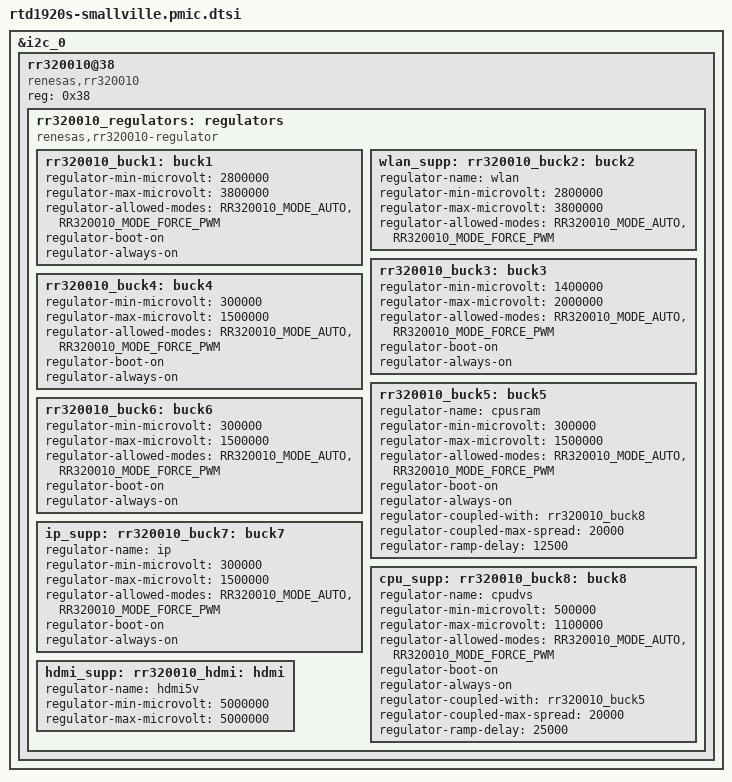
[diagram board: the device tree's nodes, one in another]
#include <dt-bindings/regulator/rr320010-regulator.h>

&i2c_0 {
	status = "okay";

	rr320010@38 {
		compatible = "renesas,rr320010";
		reg = <0x38>;

		rr320010_regulators: regulators {
			compatible = "renesas,rr320010-regulator";

			rr320010_buck1: buck1 {
				regulator-min-microvolt = <2800000>;
				regulator-max-microvolt = <3800000>;
				regulator-allowed-modes = <RR320010_MODE_AUTO>,
							  <RR320010_MODE_FORCE_PWM>;
				regulator-boot-on;
				regulator-always-on;
			};

			wlan_supp:
			rr320010_buck2: buck2 {
				regulator-name = "wlan";
				regulator-min-microvolt = <2800000>;
				regulator-max-microvolt = <3800000>;
				regulator-allowed-modes = <RR320010_MODE_AUTO>,
							  <RR320010_MODE_FORCE_PWM>;
			};

			rr320010_buck3: buck3 {
				regulator-min-microvolt = <1400000>;
				regulator-max-microvolt = <2000000>;
				regulator-allowed-modes = <RR320010_MODE_AUTO>,
							  <RR320010_MODE_FORCE_PWM>;
				regulator-boot-on;
				regulator-always-on;
			};

			rr320010_buck4: buck4 {
				regulator-min-microvolt = <300000>;
				regulator-max-microvolt = <1500000>;
				regulator-allowed-modes = <RR320010_MODE_AUTO>,
							  <RR320010_MODE_FORCE_PWM>;
				regulator-boot-on;
				regulator-always-on;
			};

			rr320010_buck5: buck5 {
				regulator-name = "cpusram";
				regulator-min-microvolt = <300000>;
				regulator-max-microvolt = <1500000>;
				regulator-allowed-modes = <RR320010_MODE_AUTO>,
							  <RR320010_MODE_FORCE_PWM>;
				regulator-boot-on;
				regulator-always-on;
				regulator-coupled-with = <&rr320010_buck8>;
				regulator-coupled-max-spread = <20000>;
				regulator-ramp-delay = <12500>;
			};

			rr320010_buck6: buck6 {
				regulator-min-microvolt = <300000>;
				regulator-max-microvolt = <1500000>;
				regulator-allowed-modes = <RR320010_MODE_AUTO>,
							  <RR320010_MODE_FORCE_PWM>;
				regulator-boot-on;
				regulator-always-on;
			};

			ip_supp:
			rr320010_buck7: buck7 {
				regulator-name = "ip";
				regulator-min-microvolt = <300000>;
				regulator-max-microvolt = <1500000>;
				regulator-allowed-modes = <RR320010_MODE_AUTO>,
							  <RR320010_MODE_FORCE_PWM>;
				regulator-boot-on;
				regulator-always-on;
			};

			cpu_supp:
			rr320010_buck8: buck8 {
				regulator-name = "cpudvs";
				regulator-min-microvolt = <500000>;
				regulator-max-microvolt = <1100000>;
				regulator-allowed-modes = <RR320010_MODE_AUTO>,
							  <RR320010_MODE_FORCE_PWM>;
				regulator-boot-on;
				regulator-always-on;
				regulator-coupled-with = <&rr320010_buck5>;
				regulator-coupled-max-spread = <20000>;
				regulator-ramp-delay = <25000>;
			};

			hdmi_supp:
			rr320010_hdmi: hdmi {
				regulator-name = "hdmi5v";
				regulator-min-microvolt = <5000000>;
				regulator-max-microvolt = <5000000>;
			};
		};
	};
};
